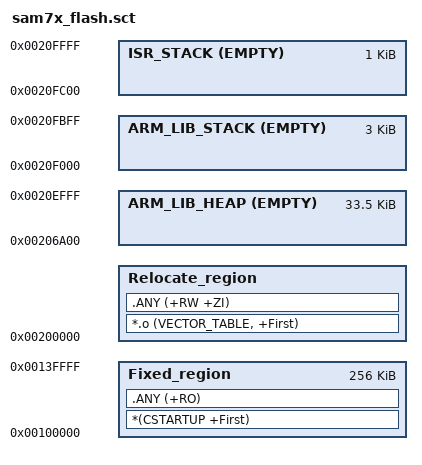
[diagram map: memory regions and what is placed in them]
;****************************************************************
;* SAM7X linker scatter file (running code from internal FLASH) *
;****************************************************************
 
Load_region 0x100000 0x40000
{
    Fixed_region 0x100000 0x40000
    {
        *(CSTARTUP +First)
        .ANY (+RO)
    }
  	
    Relocate_region 0x200000
    {
        *.o (VECTOR_TABLE, +First)   
        .ANY (+RW +ZI)
    }
    
    ScatterAssert(ImageLength(Relocate_region) < 0x5A00)
    
    ARM_LIB_HEAP 0x206A00 EMPTY 0x8600
    {
    }
    
    ARM_LIB_STACK 0x20FC00 EMPTY -0xC00
    {
    }
    
    ISR_STACK 0x210000 EMPTY -0x400
    {
    }
}
